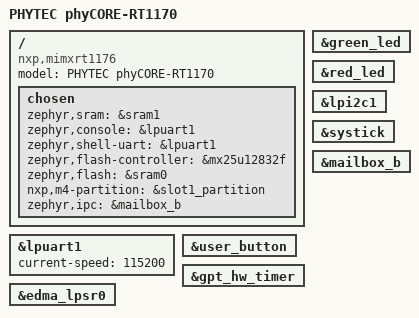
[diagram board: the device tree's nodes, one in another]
/*
 * Copyright 2024, PHYTEC America, LLC
 *
 * SPDX-License-Identifier: Apache-2.0
 */

/dts-v1/;

#include <nxp/nxp_rt11xx_cm4.dtsi>
#include "phycore_rt1170.dtsi"

/ {
	model = "PHYTEC phyCORE-RT1170";
	compatible = "nxp,mimxrt1176";

	chosen {
		/*
		 * Note: when using DMA, the SRAM region must be set to
		 * a memory region that is not cached by the chip. If the chosen
		 * sram region is changed and DMA is in use, you will
		 * encounter issues!
		 */
		zephyr,sram = &sram1;
		zephyr,console = &lpuart1;
		zephyr,shell-uart = &lpuart1;
		zephyr,flash-controller = &mx25u12832f;
		zephyr,flash = &sram0;
		nxp,m4-partition = &slot1_partition;
		zephyr,ipc = &mailbox_b;
	};
};

&lpuart1 {
	status = "okay";
	current-speed = <115200>;
};

&user_button {
	status = "okay";
};

&green_led {
	status = "okay";
};

&red_led {
	status = "okay";
};

&lpi2c1 {
	status = "okay";
};

/* GPT and Systick are enabled. If power management is enabled, the GPT
 * timer will be used instead of systick, as allows the core clock to
 * be gated.
 */
&gpt_hw_timer {
	status = "okay";
};

&systick {
	status = "okay";
};

&edma_lpsr0 {
	status = "okay";
};

&mailbox_b {
	status = "okay";
};
